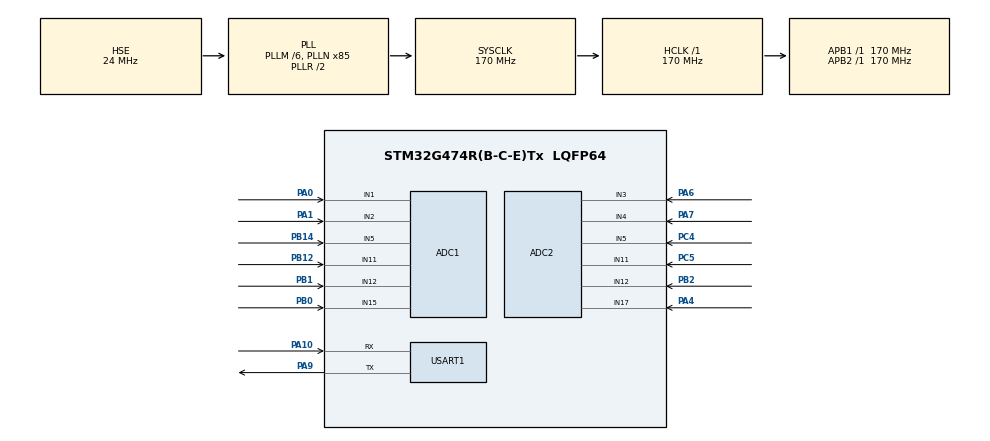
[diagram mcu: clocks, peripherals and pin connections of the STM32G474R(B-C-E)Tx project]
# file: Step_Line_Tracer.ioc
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ADC1.Channel-0\#ChannelRegularConversion=ADC_CHANNEL_1
ADC1.Channel-1\#ChannelRegularConversion=ADC_CHANNEL_2
ADC1.Channel-2\#ChannelRegularConversion=ADC_CHANNEL_5
ADC1.Channel-3\#ChannelRegularConversion=ADC_CHANNEL_11
ADC1.Channel-4\#ChannelRegularConversion=ADC_CHANNEL_12
ADC1.Channel-5\#ChannelRegularConversion=ADC_CHANNEL_15
ADC1.ContinuousConvMode=ENABLE
ADC1.DMAContinuousRequests=ENABLE
ADC1.NbrOfConversion=6
ADC1.NbrOfConversionFlag=1
ADC1.OffsetNumber-0\#ChannelRegularConversion=ADC_OFFSET_NONE
ADC1.OffsetNumber-1\#ChannelRegularConversion=ADC_OFFSET_NONE
ADC1.OffsetNumber-2\#ChannelRegularConversion=ADC_OFFSET_NONE
ADC1.OffsetNumber-3\#ChannelRegularConversion=ADC_OFFSET_NONE
ADC1.OffsetNumber-4\#ChannelRegularConversion=ADC_OFFSET_NONE
ADC1.OffsetNumber-5\#ChannelRegularConversion=ADC_OFFSET_NONE
ADC1.Overrun=ADC_OVR_DATA_OVERWRITTEN
ADC1.Rank-0\#ChannelRegularConversion=1
ADC1.Rank-1\#ChannelRegularConversion=2
ADC1.Rank-2\#ChannelRegularConversion=3
ADC1.Rank-3\#ChannelRegularConversion=4
ADC1.Rank-4\#ChannelRegularConversion=5
ADC1.Rank-5\#ChannelRegularConversion=6
ADC1.SamplingTime-0\#ChannelRegularConversion=ADC_SAMPLETIME_640CYCLES_5
ADC1.SamplingTime-1\#ChannelRegularConversion=ADC_SAMPLETIME_640CYCLES_5
ADC1.SamplingTime-2\#ChannelRegularConversion=ADC_SAMPLETIME_640CYCLES_5
ADC1.SamplingTime-3\#ChannelRegularConversion=ADC_SAMPLETIME_640CYCLES_5
ADC1.SamplingTime-4\#ChannelRegularConversion=ADC_SAMPLETIME_640CYCLES_5
ADC1.SamplingTime-5\#ChannelRegularConversion=ADC_SAMPLETIME_640CYCLES_5
ADC1.master=1
ADC2.Channel-0\#ChannelRegularConversion=ADC_CHANNEL_3
ADC2.Channel-1\#ChannelRegularConversion=ADC_CHANNEL_4
ADC2.Channel-2\#ChannelRegularConversion=ADC_CHANNEL_5
ADC2.Channel-3\#ChannelRegularConversion=ADC_CHANNEL_11
ADC2.Channel-4\#ChannelRegularConversion=ADC_CHANNEL_12
ADC2.Channel-5\#ChannelRegularConversion=ADC_CHANNEL_17
ADC2.ContinuousConvMode=ENABLE
ADC2.DMAContinuousRequests=ENABLE
ADC2.NbrOfConversion=6
ADC2.NbrOfConversionFlag=1
ADC2.OffsetNumber-0\#ChannelRegularConversion=ADC_OFFSET_NONE
ADC2.OffsetNumber-1\#ChannelRegularConversion=ADC_OFFSET_NONE
ADC2.OffsetNumber-2\#ChannelRegularConversion=ADC_OFFSET_NONE
ADC2.OffsetNumber-3\#ChannelRegularConversion=ADC_OFFSET_NONE
ADC2.OffsetNumber-4\#ChannelRegularConversion=ADC_OFFSET_NONE
ADC2.OffsetNumber-5\#ChannelRegularConversion=ADC_OFFSET_NONE
ADC2.Overrun=ADC_OVR_DATA_OVERWRITTEN
ADC2.Rank-0\#ChannelRegularConversion=1
ADC2.Rank-1\#ChannelRegularConversion=2
ADC2.Rank-2\#ChannelRegularConversion=3
ADC2.Rank-3\#ChannelRegularConversion=4
ADC2.Rank-4\#ChannelRegularConversion=5
ADC2.Rank-5\#ChannelRegularConversion=6
ADC2.SamplingTime-0\#ChannelRegularConversion=ADC_SAMPLETIME_640CYCLES_5
ADC2.SamplingTime-1\#ChannelRegularConversion=ADC_SAMPLETIME_640CYCLES_5
ADC2.SamplingTime-2\#ChannelRegularConversion=ADC_SAMPLETIME_640CYCLES_5
ADC2.SamplingTime-3\#ChannelRegularConversion=ADC_SAMPLETIME_640CYCLES_5
ADC2.SamplingTime-4\#ChannelRegularConversion=ADC_SAMPLETIME_640CYCLES_5
ADC2.SamplingTime-5\#ChannelRegularConversion=ADC_SAMPLETIME_640CYCLES_5
Dma.ADC1.0.Direction=DMA_PERIPH_TO_MEMORY
Dma.ADC1.0.EventEnable=DISABLE
Dma.ADC1.0.Instance=DMA1_Channel1
Dma.ADC1.0.MemDataAlignment=DMA_MDATAALIGN_HALFWORD
Dma.ADC1.0.MemInc=DMA_MINC_ENABLE
Dma.ADC1.0.Mode=DMA_CIRCULAR
Dma.ADC1.0.PeriphDataAlignment=DMA_PDATAALIGN_HALFWORD
Dma.ADC1.0.PeriphInc=DMA_PINC_DISABLE
Dma.ADC1.0.Polarity=HAL_DMAMUX_REQ_GEN_RISING
Dma.ADC1.0.Priority=DMA_PRIORITY_LOW
Dma.ADC1.0.RequestNumber=1
Dma.ADC1.0.SignalID=NONE
Dma.ADC1.0.SyncEnable=DISABLE
Dma.ADC1.0.SyncPolarity=HAL_DMAMUX_SYNC_NO_EVENT
Dma.ADC1.0.SyncRequestNumber=1
Dma.ADC1.0.SyncSignalID=NONE
Dma.ADC2.1.Direction=DMA_PERIPH_TO_MEMORY
Dma.ADC2.1.EventEnable=DISABLE
Dma.ADC2.1.Instance=DMA1_Channel2
Dma.ADC2.1.MemDataAlignment=DMA_MDATAALIGN_HALFWORD
Dma.ADC2.1.MemInc=DMA_MINC_ENABLE
Dma.ADC2.1.Mode=DMA_CIRCULAR
Dma.ADC2.1.PeriphDataAlignment=DMA_PDATAALIGN_HALFWORD
Dma.ADC2.1.PeriphInc=DMA_PINC_DISABLE
Dma.ADC2.1.Polarity=HAL_DMAMUX_REQ_GEN_RISING
Dma.ADC2.1.Priority=DMA_PRIORITY_LOW
Dma.ADC2.1.RequestNumber=1
Dma.ADC2.1.SignalID=NONE
Dma.ADC2.1.SyncEnable=DISABLE
Dma.ADC2.1.SyncPolarity=HAL_DMAMUX_SYNC_NO_EVENT
Dma.ADC2.1.SyncRequestNumber=1
Dma.ADC2.1.SyncSignalID=NONE
Dma.Request0=ADC1
Dma.Request1=ADC2
Mcu.Family=STM32G4
Mcu.Name=STM32G474R(B-C-E)Tx
Mcu.Package=LQFP64
NVIC.DMA1_Channel1_IRQn=true\:0\:0\:false\:false\:true\:false\:true\:true
NVIC.DMA1_Channel2_IRQn=true\:0\:0\:false\:false\:true\:false\:true\:true
NVIC.PriorityGroup=NVIC_PRIORITYGROUP_4
PA0.Mode=IN1-Single-Ended
PA0.Signal=ADC1_IN1
PA1.Mode=IN2-Single-Ended
PA1.Signal=ADC1_IN2
PA10.Mode=Asynchronous
PA10.Signal=USART1_RX
PA13.Signal=SYS_JTMS-SWDIO
PA14.Signal=SYS_JTCK-SWCLK
PA4.Mode=IN17-Single-Ended
PA4.Signal=ADC2_IN17
PA6.Mode=IN3-Single-Ended
PA6.Signal=ADC2_IN3
PA7.Mode=IN4-Single-Ended
PA7.Signal=ADC2_IN4
PA9.Mode=Asynchronous
PA9.Signal=USART1_TX
PB0.Mode=IN15-Single-Ended
PB0.Signal=ADC1_IN15
PB1.Mode=IN12-Single-Ended
PB1.Signal=ADC1_IN12
PB12.Mode=IN11-Single-Ended
PB12.Signal=ADC1_IN11
PB14.Mode=IN5-Single-Ended
PB14.Signal=ADC1_IN5
PB2.Mode=IN12-Single-Ended
PB2.Signal=ADC2_IN12
PC4.Mode=IN5-Single-Ended
PC4.Signal=ADC2_IN5
PC5.Mode=IN11-Single-Ended
PC5.Signal=ADC2_IN11
PF0-OSC_IN.Mode=HSE-External-Oscillator
PF0-OSC_IN.Signal=RCC_OSC_IN
PF1-OSC_OUT.Mode=HSE-External-Oscillator
PF1-OSC_OUT.Signal=RCC_OSC_OUT
ProjectManager.HeapSize=0x200
ProjectManager.StackSize=0x400
ProjectManager.TargetToolchain=STM32CubeIDE
RCC.ADC12Freq_Value=170000000
RCC.ADC345Freq_Value=170000000
RCC.AHBFreq_Value=170000000
RCC.APB1Freq_Value=170000000
RCC.APB1TimFreq_Value=170000000
RCC.APB2Freq_Value=170000000
RCC.APB2TimFreq_Value=170000000
RCC.CortexFreq_Value=170000000
RCC.EXTERNAL_CLOCK_VALUE=12288000
RCC.HCLKFreq_Value=170000000
RCC.HSE_VALUE=24000000
RCC.HSI48_VALUE=48000000
RCC.HSI_VALUE=16000000
RCC.LSE_VALUE=32768
RCC.PLLM=RCC_PLLM_DIV6
RCC.PLLN=85
RCC.PLLSourceVirtual=RCC_PLLSOURCE_HSE
RCC.SYSCLKFreq_VALUE=170000000
RCC.SYSCLKSource=RCC_SYSCLKSOURCE_PLLCLK
RCC.USBFreq_Value=170000000
RCC.VCOOutputFreq_Value=340000000
USART1.VirtualMode-Asynchronous=VM_ASYNC
VP_SYS_VS_DBSignals.Mode=DisableDeadBatterySignals
board=custom

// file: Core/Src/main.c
/* USER CODE BEGIN Header */
/**
  ******************************************************************************
  * @file           : main.c
  * @brief          : Main program body
  ******************************************************************************
  * @attention
  *
  * Copyright (c) 2026 STMicroelectronics.
  * All rights reserved.
  *
  * This software is licensed under terms that can be found in the LICENSE file
  * in the root directory of this software component.
  * If no LICENSE file comes with this software, it is provided AS-IS.
  *
  ******************************************************************************
  */
/* USER CODE END Header */
#include "main.h"
#include "adc.h"
#include "dma.h"
#include "usart.h"
#include "gpio.h"

/* USER CODE BEGIN PD */
#define NUMTCRT_1 6 // number of tcrt 5000 that is connected to the ADC1
#define NUMTCRT_2 6 // number of tcrt 5000 that is connected to the ADC2

//                                     ^ FRONT ^
//
// <-------------- ADC1 --------------->   |   <-------------- ADC2 --------------->
//                                         |
// +-----+-----+-----+-----+-----+-----+   |   +-----+-----+-----+-----+-----+-----+
// | S1  | S2  | S3  | S4  | S5  | S6  |   |   | S7  | S8  | S9  | S10 | S11 | S12 |
// +-----+-----+-----+-----+-----+-----+   |   +-----+-----+-----+-----+-----+-----+
//                                         |
//   PA0   PA1   PB14  PB12  PB1   PB0     |     PA4   PB2   PC5   PC4   PA7   PA6    <- Pin
//   IN1   IN2   IN5   IN11  IN12  IN15    |     IN17  IN12  IN11  IN5   IN4   IN3    <- Channel
//   R1    R2    R3    R4    R5    R6      |     R6    R5    R4    R3    R2    R1     <- Rank
//  b1[0] b1[1] b1[2] b1[3] b1[4] b1[5]    |    b2[5] b2[4] b2[3] b2[2] b2[1] b2[0]   <- DMA buf
//   -11   -9    -7    -5    -3    -1      |     +1    +3    +5    +7    +9    +11    <- Weight
//                                         |
// <<< Rank 1 first                     CENTER                   Rank 1 first >>>
//                                    (error = 0)
/* USER CODE END PD */

void SystemClock_Config(void);

int main(void)
{

  /* USER CODE BEGIN 1 */
  /* =====   TCRT5000 (ADC + DMA)   ===== */
  /* DMA keeps overwriting these buffers in the background, so they are
   * volatile: the compiler must re-read them every time instead of caching.
   * Index order follows the sensor diagram above (b1[k] and b2[k] are a
   * left/right mirror pair around the center). */
  volatile uint16_t buf_tcrt_1[NUMTCRT_1] = {0,}; // adc1 data (S1~S6), updated by DMA
  volatile uint16_t buf_tcrt_2[NUMTCRT_2] = {0,}; // adc2 data (S7~S12), updated by DMA

  /* =====   PID   ===== */
  /* Use float, not double:
   * The STM32G4 (Cortex-M4F) FPU supports single precision (float) only.
   * double operations are not handled by the hardware FPU and are emulated
   * in software, which is much slower. Use float literals too (e.g. 1.0f). */
  float k_p, k_i, k_d; 					// PID coefficients (Kp, Ki, Kd), tuning constants
  float gain_p, gain_i, gain_d; 		// P, I, D term outputs, recalculated every tick (e.g. gain_p = k_p * err_curr)
  float err_curr; 						// current error (line position, -11 ~ +11, 0 = center)
  float	err_prev;						// previous error (last tick, used for D term)
  /* USER CODE END 1 */

  /* MCU Configuration--------------------------------------------------------*/

  /* Reset of all peripherals, Initializes the Flash interface and the Systick. */
  HAL_Init();

  /* Configure the system clock */
  SystemClock_Config();

  /* Initialize all configured peripherals */
  MX_GPIO_Init();
  MX_DMA_Init();
  MX_ADC1_Init();
  MX_ADC2_Init();
  MX_USART1_UART_Init();
  /* USER CODE BEGIN 2 */
  HAL_ADCEx_Calibration_Start(&hadc1, ADC_SINGLE_ENDED); 				// ADC1 Calibration
  HAL_ADCEx_Calibration_Start(&hadc2, ADC_SINGLE_ENDED);       			// ADC2 Calibration
  HAL_ADC_Start_DMA(&hadc1, (uint32_t *)buf_tcrt_1, NUMTCRT_1);		// ADC1 and ADC1_dma start
  HAL_ADC_Start_DMA(&hadc2, (uint32_t *)buf_tcrt_2, NUMTCRT_2);		// ADC2 and ADC2_dma start
  /* USER CODE END 2 */

  /* Infinite loop */
  while (1)
  {

  }
}

void SystemClock_Config(void)
{
  RCC_OscInitTypeDef RCC_OscInitStruct = {0};
  RCC_ClkInitTypeDef RCC_ClkInitStruct = {0};

  /** Configure the main internal regulator output voltage
  */
  HAL_PWREx_ControlVoltageScaling(PWR_REGULATOR_VOLTAGE_SCALE1_BOOST);

  /** Initializes the RCC Oscillators according to the specified parameters
  * in the RCC_OscInitTypeDef structure.
  */
  RCC_OscInitStruct.OscillatorType = RCC_OSCILLATORTYPE_HSE;
  RCC_OscInitStruct.HSEState = RCC_HSE_ON;
  RCC_OscInitStruct.PLL.PLLState = RCC_PLL_ON;
  RCC_OscInitStruct.PLL.PLLSource = RCC_PLLSOURCE_HSE;
  RCC_OscInitStruct.PLL.PLLM = RCC_PLLM_DIV6;
  RCC_OscInitStruct.PLL.PLLN = 85;
  RCC_OscInitStruct.PLL.PLLP = RCC_PLLP_DIV2;
  RCC_OscInitStruct.PLL.PLLQ = RCC_PLLQ_DIV2;
  RCC_OscInitStruct.PLL.PLLR = RCC_PLLR_DIV2;
  if (HAL_RCC_OscConfig(&RCC_OscInitStruct) != HAL_OK)
  {
    Error_Handler();
  }

  /** Initializes the CPU, AHB and APB buses clocks
  */
  RCC_ClkInitStruct.ClockType = RCC_CLOCKTYPE_HCLK|RCC_CLOCKTYPE_SYSCLK
                              |RCC_CLOCKTYPE_PCLK1|RCC_CLOCKTYPE_PCLK2;
  RCC_ClkInitStruct.SYSCLKSource = RCC_SYSCLKSOURCE_PLLCLK;
  RCC_ClkInitStruct.AHBCLKDivider = RCC_SYSCLK_DIV1;
  RCC_ClkInitStruct.APB1CLKDivider = RCC_HCLK_DIV1;
  RCC_ClkInitStruct.APB2CLKDivider = RCC_HCLK_DIV1;

  if (HAL_RCC_ClockConfig(&RCC_ClkInitStruct, FLASH_LATENCY_4) != HAL_OK)
  {
    Error_Handler();
  }
}

void Error_Handler(void)
{
  __disable_irq();
  while (1)
  {
  }
}
